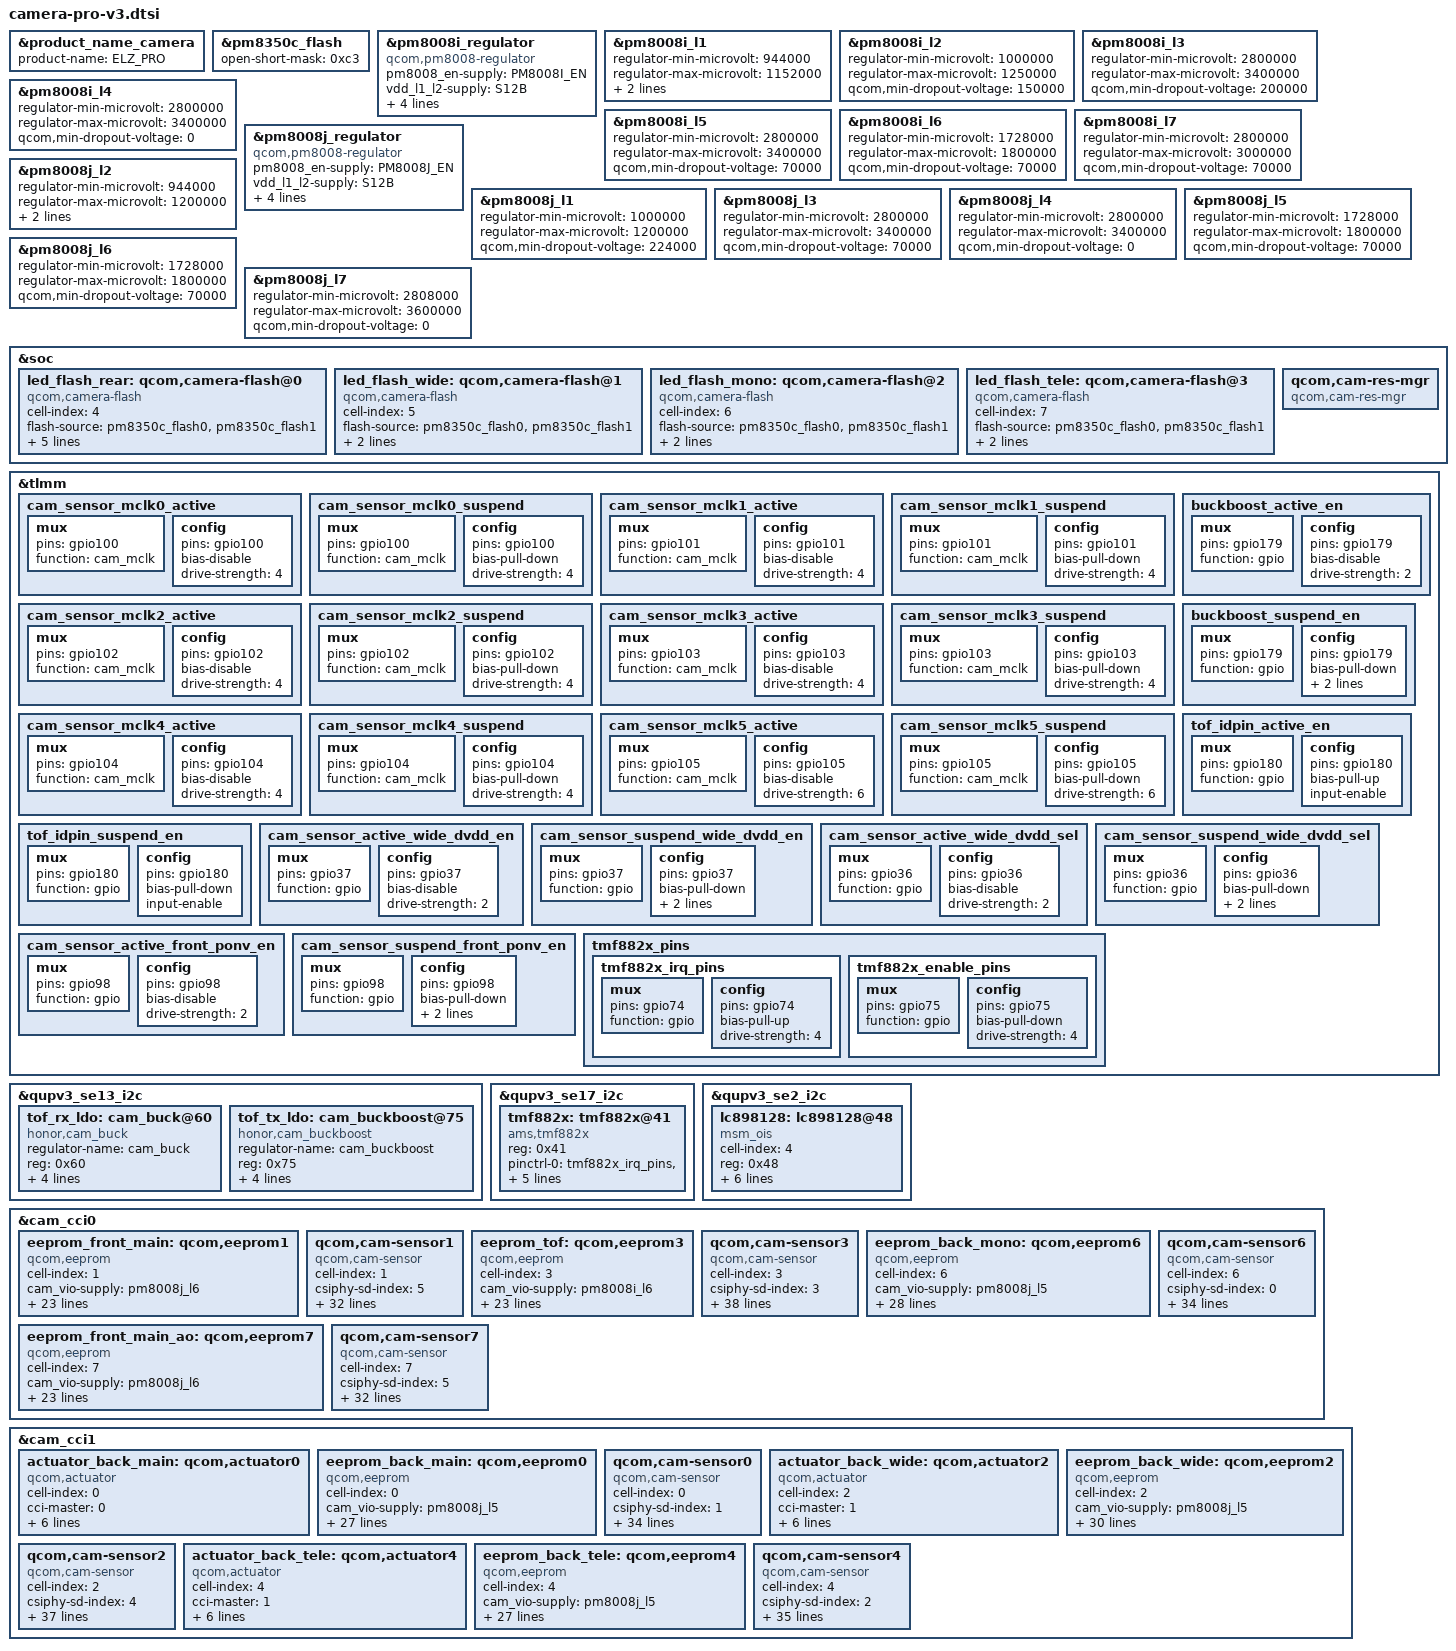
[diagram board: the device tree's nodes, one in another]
#include <dt-bindings/clock/qcom,camcc-lahaina.h>
#include "../isolate-qrd.dtsi"

&product_name_camera {
	product-name = "ELZ_PRO";
};

&pm8350c_flash {
	open-short-mask = /bits/ 8 <0xc3>;
};

&pm8008i_regulator {
	compatible = "qcom,pm8008-regulator";
	#address-cells = <1>;
	#size-cells = <0>;

	pm8008_en-supply = <&PM8008I_EN>;
	vdd_l1_l2-supply = <&S12B>;
	vdd_l3_l4-supply = <&BOB>;
	vdd_l5-supply = <&BOB>;
	vdd_l6-supply = <&S1C>;
	vdd_l7-supply = <&BOB>;
};

&pm8008i_l1 {
	regulator-min-microvolt = <944000>;
	regulator-max-microvolt = <1152000>;
	qcom,min-dropout-voltage = <100000>;
	qcom,hpm-min-load = <30000>;
};

&pm8008i_l2 {
	regulator-min-microvolt = <1000000>;
	regulator-max-microvolt = <1250000>;
	qcom,min-dropout-voltage = <150000>;
};

&pm8008i_l3 {
	regulator-min-microvolt = <2800000>;
	regulator-max-microvolt = <3400000>;
	qcom,min-dropout-voltage = <200000>;
};

&pm8008i_l4 {
	regulator-min-microvolt = <2800000>;
	regulator-max-microvolt = <3400000>;
	qcom,min-dropout-voltage = <0>;
};

&pm8008i_l5 {
	regulator-min-microvolt = <2800000>;
	regulator-max-microvolt = <3400000>;
	qcom,min-dropout-voltage = <70000>;
};

&pm8008i_l6 {
	regulator-min-microvolt = <1728000>;
	regulator-max-microvolt = <1800000>;
	qcom,min-dropout-voltage = <70000>;
};

&pm8008i_l7 {
	regulator-min-microvolt = <2800000>;
	regulator-max-microvolt = <3000000>;
	qcom,min-dropout-voltage = <70000>;
};

&pm8008j_regulator {
	compatible = "qcom,pm8008-regulator";
	#address-cells = <1>;
	#size-cells = <0>;

	pm8008_en-supply = <&PM8008J_EN>;
	vdd_l1_l2-supply = <&S12B>;
	vdd_l3_l4-supply = <&BOB>;
	vdd_l5-supply = <&S1C>;
	vdd_l6-supply = <&S1C>;
	vdd_l7-supply = <&BOB>;
};

&pm8008j_l1 {
	regulator-min-microvolt = <1000000>;
	regulator-max-microvolt = <1200000>;
	qcom,min-dropout-voltage = <224000>;
};

&pm8008j_l2 {
	regulator-min-microvolt = <944000>;
	regulator-max-microvolt = <1200000>;
	qcom,min-dropout-voltage = <0>;
	qcom,hpm-min-load = <30000>;
};

&pm8008j_l3 {
	regulator-min-microvolt = <2800000>;
	regulator-max-microvolt = <3400000>;
	qcom,min-dropout-voltage = <70000>;
};

&pm8008j_l4 {
	regulator-min-microvolt = <2800000>;
	regulator-max-microvolt = <3400000>;
	qcom,min-dropout-voltage = <0>;
};

&pm8008j_l5 {
	regulator-min-microvolt = <1728000>;
	regulator-max-microvolt = <1800000>;
	qcom,min-dropout-voltage = <70000>;
};

&pm8008j_l6 {
	regulator-min-microvolt = <1728000>;
	regulator-max-microvolt = <1800000>;
	qcom,min-dropout-voltage = <70000>;
};

&pm8008j_l7 {
	regulator-min-microvolt = <2808000>;
	regulator-max-microvolt = <3600000>;
	qcom,min-dropout-voltage = <0>;
};

&soc {
	led_flash_rear: qcom,camera-flash@0 {
		cell-index = <4>;
		compatible = "qcom,camera-flash";
		flash-source = <&pm8350c_flash0 &pm8350c_flash1>;
		torch-source = <&pm8350c_torch0 &pm8350c_torch1>;
		switch-source = <&pm8350c_switch2>;
		torch-light-num = <0>;
		torch-light-name = "torch-light0";
		flash_thermal;
		status = "ok";
	};

	led_flash_wide: qcom,camera-flash@1 {
		cell-index = <5>;
		compatible = "qcom,camera-flash";
		flash-source = <&pm8350c_flash0 &pm8350c_flash1>;
		torch-source = <&pm8350c_torch0 &pm8350c_torch1>;
		switch-source = <&pm8350c_switch2>;
		status = "ok";
	};

	led_flash_mono: qcom,camera-flash@2 {
		cell-index = <6>;
		compatible = "qcom,camera-flash";
		flash-source = <&pm8350c_flash0 &pm8350c_flash1>;
		torch-source = <&pm8350c_torch0 &pm8350c_torch1>;
		switch-source = <&pm8350c_switch2>;
		status = "ok";
	};

	led_flash_tele: qcom,camera-flash@3 {
		cell-index = <7>;
		compatible = "qcom,camera-flash";
		flash-source = <&pm8350c_flash0 &pm8350c_flash1>;
		torch-source = <&pm8350c_torch0 &pm8350c_torch1>;
		switch-source = <&pm8350c_switch2>;
		status = "ok";
	};

	qcom,cam-res-mgr {
		compatible = "qcom,cam-res-mgr";
		status = "ok";
	};
};

&tlmm {
	cam_sensor_mclk0_active: cam_sensor_mclk0_active {
		/* MCLK0 */
		mux {
			pins = "gpio100";
			function = "cam_mclk";
		};

		config {
			pins = "gpio100";
			bias-disable; /* No PULL */
			drive-strength = <4>; /* 4 MA */
		};
	};

	cam_sensor_mclk0_suspend: cam_sensor_mclk0_suspend {
		/* MCLK0 */
		mux {
			pins = "gpio100";
			function = "cam_mclk";
		};

		config {
			pins = "gpio100";
			bias-pull-down; /* PULL DOWN */
			drive-strength = <4>; /* 4 MA */
		};
	};

	cam_sensor_mclk1_active: cam_sensor_mclk1_active {
		/* MCLK1 */
		mux {
			pins = "gpio101";
			function = "cam_mclk";
		};

		config {
			pins = "gpio101";
			bias-disable; /* No PULL */
			drive-strength = <4>; /* 4 MA */
		};
	};

	cam_sensor_mclk1_suspend: cam_sensor_mclk1_suspend {
		/* MCLK1 */
		mux {
			pins = "gpio101";
			function = "cam_mclk";
		};

		config {
			pins = "gpio101";
			bias-pull-down; /* PULL DOWN */
			drive-strength = <4>; /* 4 MA */
		};
	};

	cam_sensor_mclk2_active: cam_sensor_mclk2_active {
		/* MCLK2 */
		mux {
			pins = "gpio102";
			function = "cam_mclk";
		};

		config {
			pins = "gpio102";
			bias-disable; /* No PULL */
			drive-strength = <4>; /* 4 MA */
		};
	};

	cam_sensor_mclk2_suspend: cam_sensor_mclk2_suspend {
		/* MCLK2 */
		mux {
			pins = "gpio102";
			function = "cam_mclk";
		};

		config {
			pins = "gpio102";
			bias-pull-down; /* PULL DOWN */
			drive-strength = <4>; /* 4 MA */
		};
	};

	cam_sensor_mclk3_active: cam_sensor_mclk3_active {
		/* MCLK3 */
		mux {
			pins = "gpio103";
			function = "cam_mclk";
		};

		config {
			pins = "gpio103";
			bias-disable; /* No PULL */
			drive-strength = <4>; /* 4 MA */
		};
	};

	cam_sensor_mclk3_suspend: cam_sensor_mclk3_suspend {
		/* MCLK3 */
		mux {
			pins = "gpio103";
			function = "cam_mclk";
		};

		config {
			pins = "gpio103";
			bias-pull-down; /* PULL DOWN */
			drive-strength = <4>; /* 4 MA */
		};
	};

	cam_sensor_mclk4_active: cam_sensor_mclk4_active {
		/* MCLK4 */
		mux {
			pins = "gpio104";
			function = "cam_mclk";
		};

		config {
			pins = "gpio104";
			bias-disable; /* No PULL */
			drive-strength = <4>; /* 4 MA */
		};
	};

	cam_sensor_mclk4_suspend: cam_sensor_mclk4_suspend {
		/* MCLK4 */
		mux {
			pins = "gpio104";
			function = "cam_mclk";
		};

		config {
			pins = "gpio104";
			bias-pull-down; /* PULL DOWN */
			drive-strength = <4>; /* 4 MA */
		};
	};

	cam_sensor_mclk5_active: cam_sensor_mclk5_active {
		/* MCLK5 */
		mux {
			pins = "gpio105";
			function = "cam_mclk";
		};

		config {
			pins = "gpio105";
			bias-disable; /* No PULL */
			drive-strength = <6>; /* 6 MA */
		};
	};

	cam_sensor_mclk5_suspend: cam_sensor_mclk5_suspend {
		/* MCLK5 */
		mux {
			pins = "gpio105";
			function = "cam_mclk";
		};

		config {
			pins = "gpio105";
			bias-pull-down; /* PULL DOWN */
			drive-strength = <6>; /* 6 MA */
		};
	};

	buckboost_active_en: buckboost_active_en {
		/* xbuckboot en */
		mux {
			pins = "gpio179";
			function = "gpio";
		};

		config {
			pins = "gpio179";
			bias-disable; /* No PULL */
			drive-strength = <2>; /* 2 MA */
		};
	};

	buckboost_suspend_en: buckboost_suspend_en {
		 /* xbuckboot en */
		mux {
			pins = "gpio179";
			function = "gpio";
		};

		config {
			pins = "gpio179";
			bias-pull-down; /* PULL DOWN */
			drive-strength = <2>; /* 2 MA */
			output-low;
		};
	};

	tof_idpin_active_en: tof_idpin_active_en {
		mux {
			pins = "gpio180";
			function = "gpio";
		};

		config {
			pins = "gpio180";
			bias-pull-up;
			input-enable;
		};
	};

	tof_idpin_suspend_en: tof_idpin_suspend_en {
		mux {
			pins = "gpio180";
			function = "gpio";
		};

		config {
			pins = "gpio180";
			bias-pull-down;
			input-enable;
		};
	};

	cam_sensor_active_wide_dvdd_en: cam_sensor_active_wide_dvdd_en {
		/* dvdd enable */
		mux {
			pins = "gpio37";
			function = "gpio";
		};

		config {
			pins = "gpio37";
			bias-disable; /* No PULL */
			drive-strength = <2>; /* 2 MA */
		};
	};

	cam_sensor_suspend_wide_dvdd_en: cam_sensor_suspend_wide_dvdd_en {
		/* dvdd disable */
		mux {
			pins = "gpio37";
			function = "gpio";
		};

		config {
			pins = "gpio37";
			bias-pull-down; /* PULL DOWN */
			drive-strength = <2>; /* 2 MA */
			output-low;
		};
	};

	cam_sensor_active_wide_dvdd_sel: cam_sensor_active_wide_dvdd_sel {
		/* dvdd enable */
		mux {
			pins = "gpio36";
			function = "gpio";
		};

		config {
			pins = "gpio36";
			bias-disable; /* No PULL */
			drive-strength = <2>; /* 2 MA */
		};
	};

	cam_sensor_suspend_wide_dvdd_sel: cam_sensor_suspend_wide_dvdd_sel {
		/* dvdd disable */
		mux {
			pins = "gpio36";
			function = "gpio";
		};

		config {
			pins = "gpio36";
			bias-pull-down; /* PULL DOWN */
			drive-strength = <2>; /* 2 MA */
			output-low;
		};
	};

    cam_sensor_active_front_ponv_en: cam_sensor_active_front_ponv_en {
		/* dvdd enable */
		mux {
			pins = "gpio98";
			function = "gpio";
		};

		config {
			pins = "gpio98";
			bias-disable; /* No PULL */
			drive-strength = <2>; /* 2 MA */
		};
	};

    cam_sensor_suspend_front_ponv_en: cam_sensor_suspend_front_ponv_en {
		/* dvdd disable */
		mux {
			pins = "gpio98";
			function = "gpio";
		};

		config {
			pins = "gpio98";
			bias-pull-down; /* PULL DOWN */
			drive-strength = <2>; /* 2 MA */
			output-low;
		};
	};

	tmf882x_pins: tmf882x_pins {
		tmf882x_irq_pins: tmf882x_irq_pins {
			mux {
				pins = "gpio74";
				function = "gpio";
			};

			config {
				pins = "gpio74";
				bias-pull-up; /* PULL UP */
				drive-strength = <4>; /* 4 MA */
			};
		};

		tmf882x_enable_pins: tmf882x_enable_pins {
			mux {
				pins = "gpio75";
				function = "gpio";
			};

			config {
				pins = "gpio75";
				bias-pull-down; /* PULL DOWN */
				drive-strength = <4>; /* 4 MA */
			};
		};
	};
};

&qupv3_se13_i2c {
	tof_rx_ldo: cam_buck@60 {
		compatible = "honor,cam_buck";
		regulator-name = "cam_buck";
		reg = <0x60>;
		#address-cells = <1>;
		#size-cells = <0>;
		regulator-min-microvolt = <600000>;
		regulator-max-microvolt = <1300000>;
		suspend-voltage-selector = <1>;
		enable-gpio = <&tlmm 97 0>;
	};

	tof_tx_ldo: cam_buckboost@75 {
		compatible = "honor,cam_buckboost";
		regulator-name = "cam_buckboost";
		reg = <0x75>;
		#address-cells = <1>;
		#size-cells = <0>;
		regulator-min-microvolt = <2025000>; // 2.025v
		regulator-max-microvolt = <5200000>; // 5.2v
		suspend-voltage-selector = <1>;
		enable-gpio = <&tlmm 179 0>;
	};
};

&qupv3_se17_i2c {
	#address-cells = <1>;
	#size-cells = <0>;
	status = "ok";
	tmf882x: tmf882x@41 {
		compatible = "ams,tmf882x";
		reg = <0x41>; /* x41 for HW, x39 for test chip */
		pinctrl-names = "default";
		pinctrl-0 = <&tmf882x_irq_pins>,
				<&tmf882x_enable_pins>;

		interrupt-parent = <&tlmm>;
		interrupts = <74 8>; /*high-to-low trigger*/
		irq-gpios = <&tlmm 74 0>; /*pin38 on header*/
		enable-gpios = <&tlmm 75 0>; /*pin36 on header*/
        status = "ok";
    };
};

&qupv3_se2_i2c {
	#address-cells = <1>;
	#size-cells = <0>;
	status = "ok";
	lc898128: lc898128@48 {
		cell-index = <4>;
		compatible = "msm_ois";
		reg = <0x48>;
		cam_vaf-supply = <&pm8008j_l7>;
		regulator-names = "cam_vaf";
		rgltr-cntrl-support;
		rgltr-min-voltage = <3300000>;
		rgltr-max-voltage = <3300000>;
		rgltr-load-current = <68000>;
		status = "ok";
	};
};

&cam_cci0 {
	eeprom_front_main: qcom,eeprom1 {
		cell-index = <1>;
		compatible = "qcom,eeprom";
		cam_vio-supply = <&pm8008j_l6>;
		cam_vana-supply = <&pm8008i_l3>;
		cam_vdig-supply = <&pm8008j_l1>;
		cam_clk-supply = <&cam_cc_titan_top_gdsc>;
		regulator-names = "cam_vio", "cam_vana",
			"cam_vdig","cam_clk";
		rgltr-cntrl-support;
		rgltr-min-voltage = <1800000 2850000 1104000 0>;
		rgltr-max-voltage = <1800000 3000000 1104000 0>;
		rgltr-load-current = <38900 77500 454000 0>;
		gpio-no-mux = <0>;
		pinctrl-names = "cam_default", "cam_suspend";
		pinctrl-0 = <&cam_sensor_mclk5_active
				&cam_sensor_active_rst5>;
		pinctrl-1 = <&cam_sensor_mclk5_suspend
				&cam_sensor_suspend_rst5>;
		gpios = <&tlmm 105 0>,
			<&tlmm 115 0>;
		gpio-reset = <1>;
		gpio-req-tbl-num = <0 1>;
		gpio-req-tbl-flags = <1 0>;
		gpio-req-tbl-label = "CAMIF_MCLK5",
					"CAM_RESET5";
		cci-master = <0>;
		status = "ok";
		clocks = <&clock_camcc CAM_CC_MCLK5_CLK>;
		clock-names = "cam_clk";
		clock-cntl-level = "nominal";
		clock-rates = <24000000>;
	};

	/* Front */
	qcom,cam-sensor1 {
		cell-index = <1>;
		compatible = "qcom,cam-sensor";
		csiphy-sd-index = <5>;
		sensor-position-roll = <270>;
		sensor-position-pitch = <0>;
		sensor-position-yaw = <0>;
		eeprom-src = <&eeprom_front_main>;
		cam_vio-supply = <&pm8008j_l6>;
		cam_vana-supply = <&pm8008i_l3>;
		cam_vdig-supply = <&pm8008j_l1>;
		cam_clk-supply = <&cam_cc_titan_top_gdsc>;
		regulator-names = "cam_vio", "cam_vana",
			"cam_vdig","cam_clk";
		rgltr-cntrl-support;
		rgltr-min-voltage = <1800000 2850000 1104000 0>;
		rgltr-max-voltage = <1800000 3000000 1104000 0>;
		rgltr-load-current = <38900 77500 454000 0>;
		gpio-no-mux = <0>;
		pinctrl-names = "cam_default", "cam_suspend";
		pinctrl-0 = <&cam_sensor_mclk5_active
				&cam_sensor_active_rst5
				&cam_sensor_active_front_ponv_en>;
		pinctrl-1 = <&cam_sensor_mclk5_suspend
				&cam_sensor_suspend_rst5
				&cam_sensor_suspend_front_ponv_en>;
		gpios = <&tlmm 105 0>,
			<&tlmm 115 0>,
			<&tlmm 98 0>;
		gpio-reset = <1>;
		gpio-custom2 = <2>;
		gpio-req-tbl-num = <0 1 2>;
		gpio-req-tbl-flags = <1 0 0>;
		gpio-req-tbl-label = "CAMIF_MCLK5",
					"CAM_RESET5",
					"CAM_PONY";
		cci-master = <0>;
		status = "ok";
		clocks = <&clock_camcc CAM_CC_MCLK5_CLK>;
		clock-names = "cam_clk";
		clock-cntl-level = "nominal";
		clock-rates = <24000000>;
	};

	eeprom_tof: qcom,eeprom3 {
		cell-index = <3>;
		compatible = "qcom,eeprom";
		cam_vio-supply = <&pm8008i_l6>; // iovdd
		cam_vdig-supply = <&tof_rx_ldo>; // dvdd
		cam_vana-supply = <&pm8008i_l4>; // avdd
		cam_clk-supply = <&cam_cc_titan_top_gdsc>; // lahaina platform config
		regulator-names = "cam_vio", "cam_vdig",
			"cam_clk", "cam_vana";
		rgltr-cntrl-support;
		rgltr-min-voltage = <1800000 1200000 0 2850000>; // iovdd, dvdd, clk, avdd
		rgltr-max-voltage = <1800000 1200000 0 3300000>;
		rgltr-load-current = <200000 29000 0 52000>;
		gpio-no-mux = <0>; // Whether GPIO muxing is enabled
		pinctrl-names = "cam_default", "cam_suspend";
		pinctrl-0 = <&cam_sensor_mclk4_active
			&cam_sensor_active_rst4>;
		pinctrl-1 = <&cam_sensor_mclk4_suspend
			&cam_sensor_suspend_rst4>;
		gpios = <&tlmm 104 0>, // MCLK GPIO
			<&tlmm 116 0>; // reset GPIO
		gpio-reset = <1>;
		gpio-req-tbl-num = <0 1>;
		gpio-req-tbl-flags = <1 0>;
		gpio-req-tbl-label = "CAMIF_MCLK4",
			"CAM_RESET4";
		cci-master = <1>;
		clocks = <&clock_camcc CAM_CC_MCLK4_CLK>;
		clock-names = "cam_clk";
		clock-cntl-level = "nominal";
		clock-rates = <24000000>;
		status = "ok";
	};

	qcom,cam-sensor3 {
		cell-index = <3>;
		compatible = "qcom,cam-sensor";
		csiphy-sd-index = <3>; // pair to cisphy4
		eeprom-src = <&eeprom_tof>;
		sensor-position-roll = <270>;
		sensor-position-pitch = <0>;
		sensor-position-yaw = <0>;
		cam_vio-supply = <&pm8008i_l6>; // iovdd
		cam_vdig-supply = <&tof_rx_ldo>; // dvdd
		cam_vana-supply = <&pm8008i_l4>; // avdd
		cam_clk-supply = <&cam_cc_titan_top_gdsc>; // lahaina platform config
		cam_vana1-supply = <&pm8008j_l7>; // AVCC33, TOF TX
		cam_v_custom1-supply = <&tof_tx_ldo>; // LDVDD 3.6V
		regulator-names = "cam_vio", "cam_vdig",
			"cam_clk", "cam_vana", "cam_vana1", "cam_v_custom1";
		rgltr-cntrl-support;
		rgltr-min-voltage = <1800000 1200000 0 2850000 3300000 4000000>; // iovdd, dvdd, clk, avdd
		rgltr-max-voltage = <1800000 1200000 0 3300000 3300000 4000000>;
		rgltr-load-current = <200000 29000 0 52000 400000 5000>;
		gpio-no-mux = <0>; // Whether GPIO muxing is enabled
		pinctrl-names = "cam_default", "cam_suspend", "tof_idpin_default", "tof_idpin_suspend";
		pinctrl-0 = <&cam_sensor_mclk4_active
			&cam_sensor_active_rst4>;
		pinctrl-1 = <&cam_sensor_mclk4_suspend
			&cam_sensor_suspend_rst4>;
		pinctrl-2 = <&tof_idpin_active_en>;
		pinctrl-3 = <&tof_idpin_suspend_en>;
		cam-tof-idpin = <&tlmm 180 0>;
		cam-tof-idpin-state = <0 0 1 1 0 1>;
		cam-tof-id = <0 1 2>; // TOF tx vscel: vertilite, lumentum, ams
		gpios = <&tlmm 104 0>, // MCLK GPIO
			<&tlmm 116 0>; // reset GPIO
		gpio-reset = <1>;
		gpio-req-tbl-num = <0 1>;
		gpio-req-tbl-flags = <1 0>;
		gpio-req-tbl-label = "CAMIF_MCLK4",
			"CAM_RESET4";
		cci-master = <1>;
		clocks = <&clock_camcc CAM_CC_MCLK4_CLK>;
		clock-names = "cam_clk";
		clock-cntl-level = "nominal";
		clock-rates = <24000000>;
		status = "ok";
	};

	/* back mono */
	eeprom_back_mono: qcom,eeprom6 {
		cell-index = <6>;
		compatible = "qcom,eeprom";
		cam_vio-supply = <&pm8008j_l5>;
		cam_vana-supply = <&pm8008j_l3>;
		cam_vdig-supply = <&pm8008i_l1>;
		cam_clk-supply = <&cam_cc_titan_top_gdsc>;
		cam_v_custom1-supply = <&pm8008j_l4>; /* afvdd */
		cam_v_custom2-supply = <&pm8008i_l6>; /* i2c bus */
		regulator-names = "cam_vio", "cam_vana",
			"cam_vdig", "cam_clk", "cam_v_custom1", "cam_v_custom2";
		rgltr-cntrl-support;
		rgltr-min-voltage = <1800000 2850000 1100000 0 3300000 1800000>;
		rgltr-max-voltage = <1800000 3000000 1200000 0 3300000 1800000>;
		rgltr-load-current = <10000 128000 600000 0 110000 29000>;
		gpio-no-mux = <0>;
		pinctrl-names = "cam_default", "cam_suspend";
		pinctrl-0 = <&cam_sensor_mclk0_active
				&cam_sensor_active_rst1>;
		pinctrl-1 = <&cam_sensor_mclk0_suspend
				&cam_sensor_suspend_rst1>;
		gpios = <&tlmm 100 0>,
			<&tlmm 16 0>;
		gpio-reset = <1>;
		gpio-req-tbl-num = <0 1>;
		gpio-req-tbl-flags = <1 0>;
		gpio-req-tbl-label = "CAMIF_MCLK0",
					"CAM_RESET1";
		cci-master = <1>;
		status = "ok";
		clocks = <&clock_camcc CAM_CC_MCLK0_CLK>;
		clock-names = "cam_clk";
		clock-cntl-level = "nominal";
		clock-rates = <24000000>;
	};

	qcom,cam-sensor6 {
		cell-index = <6>;
		compatible = "qcom,cam-sensor";
		csiphy-sd-index = <0>;
		sensor-position-roll = <90>;
		sensor-position-pitch = <0>;
		sensor-position-yaw = <180>;
		eeprom-src = <&eeprom_back_mono>;
		led-flash-src = <&led_flash_mono>;
		cam_vio-supply = <&pm8008j_l5>;
		cam_vana-supply = <&pm8008j_l3>;
		cam_vdig-supply = <&pm8008i_l1>;
		cam_clk-supply = <&cam_cc_titan_top_gdsc>;
		cam_v_custom1-supply = <&pm8008j_l4>; /* afvdd */
		cam_v_custom2-supply = <&pm8008i_l6>; /* i2c bus */
		regulator-names = "cam_vio", "cam_vana",
			"cam_vdig", "cam_clk", "cam_v_custom1", "cam_v_custom2";
		rgltr-cntrl-support;
		rgltr-min-voltage = <1800000 2850000 1100000 0 3300000 1800000>;
		rgltr-max-voltage = <1800000 3000000 1200000 0 3300000 1800000>;
		rgltr-load-current = <10000 128000 600000 0 110000 29000>;
		gpio-no-mux = <0>;
		pinctrl-names = "cam_default", "cam_suspend";
		pinctrl-0 = <&cam_sensor_mclk0_active
				&cam_sensor_active_rst1>;
		pinctrl-1 = <&cam_sensor_mclk0_suspend
				&cam_sensor_suspend_rst1>;
		gpios = <&tlmm 100 0>,
			<&tlmm 16 0>;
		gpio-reset = <1>;
		gpio-req-tbl-num = <0 1>;
		gpio-req-tbl-flags = <1 0>;
		gpio-req-tbl-label = "CAMIF_MCLK0",
					"CAM_RESET1";
		cci-master = <1>;
		status = "ok";
		clocks = <&clock_camcc CAM_CC_MCLK0_CLK>;
		clock-names = "cam_clk";
		clock-cntl-level = "nominal";
		clock-rates = <24000000>;
	};

	eeprom_front_main_ao: qcom,eeprom7 {
		cell-index = <7>;
		compatible = "qcom,eeprom";
		cam_vio-supply = <&pm8008j_l6>;
		cam_vana-supply = <&pm8008i_l3>;
		cam_vdig-supply = <&pm8008j_l1>;
		cam_clk-supply = <&cam_cc_titan_top_gdsc>;
		regulator-names = "cam_vio", "cam_vana",
			"cam_vdig","cam_clk";
		rgltr-cntrl-support;
		rgltr-min-voltage = <1800000 2850000 1104000 0>;
		rgltr-max-voltage = <1800000 3000000 1104000 0>;
		rgltr-load-current = <5000 68000 805000 0>;
		gpio-no-mux = <0>;
		pinctrl-names = "cam_default", "cam_suspend";
		pinctrl-0 = <&cam_sensor_mclk5_active
				&cam_sensor_active_rst5>;
		pinctrl-1 = <&cam_sensor_mclk5_suspend
				&cam_sensor_suspend_rst5>;
		gpios = <&tlmm 105 0>,
			<&tlmm 115 0>;
		gpio-reset = <1>;
		gpio-req-tbl-num = <0 1>;
		gpio-req-tbl-flags = <1 0>;
		gpio-req-tbl-label = "CAMIF_MCLK5",
					"CAM_RESET5";
		cci-master = <0>;
		status = "ok";
		clocks = <&clock_camcc CAM_CC_MCLK5_CLK>;
		clock-names = "cam_clk";
		clock-cntl-level = "nominal";
		clock-rates = <24000000>;
	};

    /* Front AO */
	qcom,cam-sensor7 {
		cell-index = <7>;
		compatible = "qcom,cam-sensor";
		csiphy-sd-index = <5>;
		sensor-position-roll = <270>;
		sensor-position-pitch = <0>;
		sensor-position-yaw = <0>;
		eeprom-src = <&eeprom_front_main_ao>;
		cam_vio-supply = <&pm8008j_l6>;
		cam_vana-supply = <&pm8008i_l3>;
		cam_vdig-supply = <&pm8008j_l1>;
		cam_clk-supply = <&cam_cc_titan_top_gdsc>;
		regulator-names = "cam_vio", "cam_vana",
			"cam_vdig","cam_clk";
		rgltr-cntrl-support;
		rgltr-min-voltage = <1800000 2850000 1104000 0>;
		rgltr-max-voltage = <1800000 3000000 1104000 0>;
		rgltr-load-current = <5000 68000 805000 0>;
		gpio-no-mux = <0>;
		pinctrl-names = "cam_default", "cam_suspend";
		pinctrl-0 = <&cam_sensor_mclk5_active
				&cam_sensor_active_rst5
				&cam_sensor_active_front_ponv_en>;
		pinctrl-1 = <&cam_sensor_mclk5_suspend
				&cam_sensor_suspend_rst5
				&cam_sensor_suspend_front_ponv_en>;
		gpios = <&tlmm 105 0>,
			<&tlmm 115 0>,
			<&tlmm 98 0>;
		gpio-reset = <1>;
		gpio-custom2 = <2>;
		gpio-req-tbl-num = <0 1 2>;
		gpio-req-tbl-flags = <1 0 0>;
		gpio-req-tbl-label = "CAMIF_MCLK5",
					"CAM_RESET5",
					"CAM_PONY";
		cci-master = <0>;
		status = "ok";
		clocks = <&clock_camcc CAM_CC_MCLK5_CLK>;
		clock-names = "cam_clk";
		clock-cntl-level = "nominal";
		clock-rates = <24000000>;
	};
};

&cam_cci1 {
	/* back main */
	actuator_back_main: qcom,actuator0 {
		cell-index = <0>;
		compatible = "qcom,actuator";
		cci-master = <0>;
		cam_vaf-supply = <&pm8008j_l4>;
		regulator-names = "cam_vaf";
		rgltr-cntrl-support;
		rgltr-min-voltage = <3300000>;
		rgltr-max-voltage = <3300000>;
		rgltr-load-current = <100000>;
		status = "ok";
	};

	eeprom_back_main: qcom,eeprom0 {
		cell-index = <0>;
		compatible = "qcom,eeprom";
		cam_vio-supply = <&pm8008j_l5>;
		cam_vana-supply = <&pm8008i_l5>;
		cam_vdig-supply = <&pm8008i_l2>;
		cam_clk-supply = <&cam_cc_titan_top_gdsc>;
		cam_v_custom1-supply = <&pm8008j_l4>;
		regulator-names = "cam_vio", "cam_vana",
			"cam_vdig", "cam_clk", "cam_v_custom1";
		rgltr-cntrl-support;
		rgltr-min-voltage = <1800000 2850000 1150000 0 3300000>;
		rgltr-max-voltage = <1800000 3000000 1200000 0 3300000>;
		rgltr-load-current = <73000 91000 913000 0 100000>;
		gpio-no-mux = <0>;
		pinctrl-names = "cam_default", "cam_suspend";
		pinctrl-0 = <&cam_sensor_mclk1_active
				&cam_sensor_active_rst0>;
		pinctrl-1 = <&cam_sensor_mclk1_suspend
				&cam_sensor_suspend_rst0>;
		gpios = <&tlmm 101 0>,
			<&tlmm 17 0>;
		gpio-reset = <1>;
		gpio-req-tbl-num = <0 1>;
		gpio-req-tbl-flags = <1 0>;
		gpio-req-tbl-label = "CAMIF_MCLK1",
					"CAM_RESET0";
		cci-master = <0>;
		status = "ok";
		clocks = <&clock_camcc CAM_CC_MCLK1_CLK>;
		clock-names = "cam_clk";
		clock-cntl-level = "nominal";
		clock-rates = <24000000>;
	};

	qcom,cam-sensor0 {
		cell-index = <0>;
		compatible = "qcom,cam-sensor";
		csiphy-sd-index = <1>;
		sensor-position-roll = <90>;
		sensor-position-pitch = <0>;
		sensor-position-yaw = <180>;
		eeprom-src = <&eeprom_back_main>;
		actuator-src = <&actuator_back_main>;
		led-flash-src = <&led_flash_rear>;
		cam_vio-supply = <&pm8008j_l5>;
		cam_vana-supply = <&pm8008i_l5>;
		cam_vdig-supply = <&pm8008i_l2>;
		cam_clk-supply = <&cam_cc_titan_top_gdsc>;
		cam_v_custom1-supply = <&pm8008j_l4>;
		regulator-names = "cam_vio", "cam_vana",
			"cam_vdig", "cam_clk", "cam_v_custom1";
		rgltr-cntrl-support;
		rgltr-min-voltage = <1800000 2850000 1150000 0 3300000>;
		rgltr-max-voltage = <1800000 3000000 1200000 0 3300000>;
		rgltr-load-current = <73000 91000 913000 0 100000>;
		gpio-no-mux = <0>;
		pinctrl-names = "cam_default", "cam_suspend";
		pinctrl-0 = <&cam_sensor_mclk1_active
				&cam_sensor_active_rst0>;
		pinctrl-1 = <&cam_sensor_mclk1_suspend
				&cam_sensor_suspend_rst0>;
		gpios = <&tlmm 101 0>,
			<&tlmm 17 0>;
		gpio-reset = <1>;
		gpio-req-tbl-num = <0 1>;
		gpio-req-tbl-flags = <1 0>;
		gpio-req-tbl-label = "CAMIF_MCLK1",
					"CAM_RESET0";
		cci-master = <0>;
		status = "ok";
		clocks = <&clock_camcc CAM_CC_MCLK1_CLK>;
		clock-names = "cam_clk";
		clock-cntl-level = "nominal";
		clock-rates = <24000000>;
	};

	/* back wide */
	actuator_back_wide: qcom,actuator2 {
		cell-index = <2>;
		compatible = "qcom,actuator";
		cci-master = <1>;
		cam_vaf-supply = <&pm8008j_l4>;
		regulator-names = "cam_vaf";
		rgltr-cntrl-support;
		rgltr-min-voltage = <3300000>;
		rgltr-max-voltage = <3300000>;
		rgltr-load-current = <100000>;
		status = "ok";
	};

	eeprom_back_wide: qcom,eeprom2 {
		cell-index = <2>;
		compatible = "qcom,eeprom";
		cam_vio-supply = <&pm8008j_l5>;
		cam_vana-supply = <&pm8008j_l3>;
		cam_clk-supply = <&cam_cc_titan_top_gdsc>;
		cam_v_custom1-supply = <&pm8008j_l4>; /* afvdd */
		regulator-names = "cam_vio", "cam_vana",
			"cam_clk", "cam_v_custom1";
		rgltr-cntrl-support;
		rgltr-min-voltage = <1800000 2850000 0 3300000>;
		rgltr-max-voltage = <1800000 3000000 0 3300000>;
		rgltr-load-current = <45000 45000 0 100000>;
		gpio-no-mux = <0>;
		pinctrl-names = "cam_default", "cam_suspend";
		pinctrl-0 = <&cam_sensor_mclk3_active
				&cam_sensor_active_rst3
				&cam_sensor_active_wide_dvdd_en
				&cam_sensor_active_wide_dvdd_sel>;
		pinctrl-1 = <&cam_sensor_mclk3_suspend
				&cam_sensor_suspend_rst3
				&cam_sensor_suspend_wide_dvdd_en
				&cam_sensor_suspend_wide_dvdd_sel>;
		gpios = <&tlmm 103 0>,
			<&tlmm 117 0>,
			<&tlmm 37 0>,
			<&tlmm 36 0>;
		gpio-reset = <1>;
		gpio-custom1 = <2>;
		gpio-custom2 = <3>;
		gpio-req-tbl-num = <0 1 2 3>;
		gpio-req-tbl-flags = <1 0 0 0>;
		gpio-req-tbl-label = "CAMIF_MCLK3",
					"CAM_RESET3",
					"CAM_DVDD_EN",
					"CAM_DVDD_SEL";
		cci-master = <1>;
		status = "ok";
		clocks = <&clock_camcc CAM_CC_MCLK3_CLK>;
		clock-names = "cam_clk";
		clock-cntl-level = "nominal";
		clock-rates = <24000000>;
	};

	/* back wide */
	qcom,cam-sensor2 {
		cell-index = <2>;
		compatible = "qcom,cam-sensor";
		csiphy-sd-index = <4>;
		sensor-position-roll = <90>;
		sensor-position-pitch = <0>;
		sensor-position-yaw = <180>;
		eeprom-src = <&eeprom_back_wide>;
		actuator-src = <&actuator_back_wide>;
		led-flash-src = <&led_flash_wide>;
		cam_vio-supply = <&pm8008j_l5>;
		cam_vana-supply = <&pm8008j_l3>;
		cam_clk-supply = <&cam_cc_titan_top_gdsc>;
		cam_v_custom1-supply = <&pm8008j_l4>; /* afvdd */
		regulator-names = "cam_vio", "cam_vana",
			"cam_clk", "cam_v_custom1";
		rgltr-cntrl-support;
		rgltr-min-voltage = <1800000 2850000 0 3300000>;
		rgltr-max-voltage = <1800000 3000000 0 3300000>;
		rgltr-load-current = <45000 45000 0 100000>;
		gpio-no-mux = <0>;
		pinctrl-names = "cam_default", "cam_suspend";
		pinctrl-0 = <&cam_sensor_mclk3_active
				&cam_sensor_active_rst3
				&cam_sensor_active_wide_dvdd_en
				&cam_sensor_active_wide_dvdd_sel>;
		pinctrl-1 = <&cam_sensor_mclk3_suspend
				&cam_sensor_suspend_rst3
				&cam_sensor_suspend_wide_dvdd_en
				&cam_sensor_suspend_wide_dvdd_sel>;
		gpios = <&tlmm 103 0>,
			<&tlmm 117 0>,
			<&tlmm 37 0>,
			<&tlmm 36 0>;
		gpio-reset = <1>;
		gpio-custom1 = <2>;
		gpio-custom2 = <3>;
		gpio-req-tbl-num = <0 1 2 3>;
		gpio-req-tbl-flags = <1 0 0 0>;
		gpio-req-tbl-label = "CAMIF_MCLK3",
					"CAM_RESET3",
					"CAM_DVDD_EN",
					"CAM_DVDD_SEL";
		cci-master = <1>;
		status = "ok";
		clocks = <&clock_camcc CAM_CC_MCLK3_CLK>;
		clock-names = "cam_clk";
		clock-cntl-level = "nominal";
		clock-rates = <24000000>;
	};

	/* back tele */
	actuator_back_tele: qcom,actuator4 {
		cell-index = <4>;
		compatible = "qcom,actuator";
		cci-master = <1>;
		cam_vaf-supply = <&pm8008j_l7>;
		regulator-names = "cam_vaf";
		rgltr-cntrl-support;
		rgltr-min-voltage = <3300000>;
		rgltr-max-voltage = <3300000>;
		rgltr-load-current = <330000>;
		status = "ok";
	};

	eeprom_back_tele: qcom,eeprom4 {
		cell-index = <4>;
		compatible = "qcom,eeprom";
		cam_vio-supply = <&pm8008j_l5>;
		cam_vana-supply = <&pm8008i_l7>;
		cam_vdig-supply = <&pm8008j_l2>;
		cam_clk-supply = <&cam_cc_titan_top_gdsc>;
		cam_v_custom1-supply = <&pm8008j_l7>; /* afvdd */
		regulator-names = "cam_vio", "cam_vana",
			"cam_vdig", "cam_clk", "cam_v_custom1";
		rgltr-cntrl-support;
		rgltr-min-voltage = <1800000 2850000 1154000 0 3300000>;
		rgltr-max-voltage = <1800000 3000000 1154000 0 3300000>;
		rgltr-load-current = <10000 128000 600000 0 330000>;
		gpio-no-mux = <0>;
		pinctrl-names = "cam_default", "cam_suspend";
		pinctrl-0 = <&cam_sensor_mclk2_active
				&cam_sensor_active_rst2>;
		pinctrl-1 = <&cam_sensor_mclk2_suspend
				&cam_sensor_suspend_rst2>;
		gpios = <&tlmm 102 0>,
			<&tlmm 106 0>;
		gpio-reset = <1>;
		gpio-req-tbl-num = <0 1>;
		gpio-req-tbl-flags = <1 0>;
		gpio-req-tbl-label = "CAMIF_MCLK2",
					"CAM_RESET2";
		cci-master = <1>;
		status = "ok";
		clocks = <&clock_camcc CAM_CC_MCLK2_CLK>;
		clock-names = "cam_clk";
		clock-cntl-level = "nominal";
		clock-rates = <24000000>;
	};

	qcom,cam-sensor4 {
		cell-index = <4>;
		compatible = "qcom,cam-sensor";
		csiphy-sd-index = <2>;
		sensor-position-roll = <90>;
		sensor-position-pitch = <0>;
		sensor-position-yaw = <180>;
		eeprom-src = <&eeprom_back_tele>;
		actuator-src = <&actuator_back_tele>;
		led-flash-src = <&led_flash_tele>;
		ois-src = <&lc898128>;
		cam_vio-supply = <&pm8008j_l5>;
		cam_vana-supply = <&pm8008i_l7>;
		cam_vdig-supply = <&pm8008j_l2>;
		cam_clk-supply = <&cam_cc_titan_top_gdsc>;
		cam_v_custom1-supply = <&pm8008j_l7>; /* afvdd */
		regulator-names = "cam_vio", "cam_vana",
			"cam_vdig", "cam_clk", "cam_v_custom1";
		rgltr-cntrl-support;
		rgltr-min-voltage = <1800000 2850000 1154000 0 3300000>;
		rgltr-max-voltage = <1800000 3000000 1154000 0 3300000>;
		rgltr-load-current = <10000 128000 600000 0 330000>;
		gpio-no-mux = <0>;
		pinctrl-names = "cam_default", "cam_suspend";
		pinctrl-0 = <&cam_sensor_mclk2_active
				&cam_sensor_active_rst2>;
		pinctrl-1 = <&cam_sensor_mclk2_suspend
				&cam_sensor_suspend_rst2>;
		gpios = <&tlmm 102 0>,
			<&tlmm 106 0>;
		gpio-reset = <1>;
		gpio-req-tbl-num = <0 1>;
		gpio-req-tbl-flags = <1 0>;
		gpio-req-tbl-label = "CAMIF_MCLK2",
					"CAM_RESET2";
		cci-master = <1>;
		status = "ok";
		clocks = <&clock_camcc CAM_CC_MCLK2_CLK>;
		clock-names = "cam_clk";
		clock-cntl-level = "nominal";
		clock-rates = <24000000>;
	};
};
